VERSION ""

NS_ :

BS_:

BU_: XXX

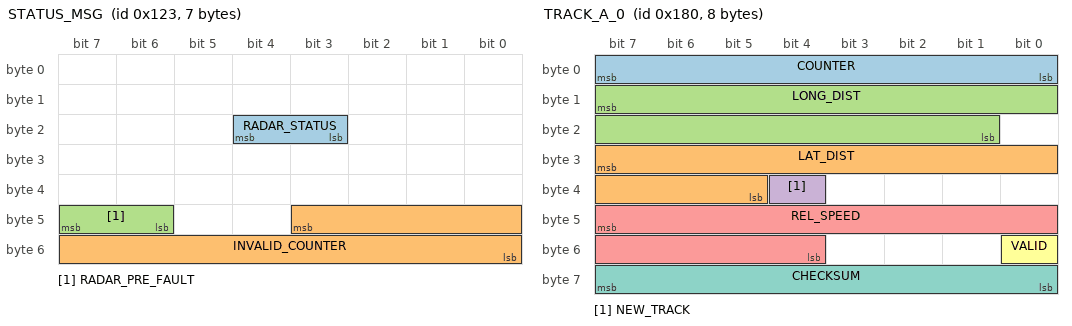
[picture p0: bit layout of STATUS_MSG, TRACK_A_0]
BO_ 291 STATUS_MSG: 7 XXX
 SG_ RADAR_STATUS : 20|2@0+ (1,0) [0|3] "" XXX
 SG_ INVALID_COUNTER : 43|12@0+ (1,0) [0|4095] "" XXX
 SG_ RADAR_PRE_FAULT : 47|2@0+ (1,0) [0|3] "" XXX

BO_ 384 TRACK_A_0: 8 XXX
 SG_ COUNTER : 7|8@0+ (1,0) [0|255] "" XXX
 SG_ LAT_DIST : 31|11@0- (0.04,0) [-50|50] "m" XXX
 SG_ LONG_DIST : 15|15@0+ (0.01,0) [0|300] "m" XXX
 SG_ NEW_TRACK : 36|1@0+ (1,0) [0|1] "" XXX
 SG_ REL_SPEED : 47|12@0- (0.025,0) [-100|100] "m/s" XXX
 SG_ VALID : 48|1@0+ (1,0) [0|1] "" XXX
 SG_ CHECKSUM : 63|8@0+ (1,0) [0|255] "" XXX

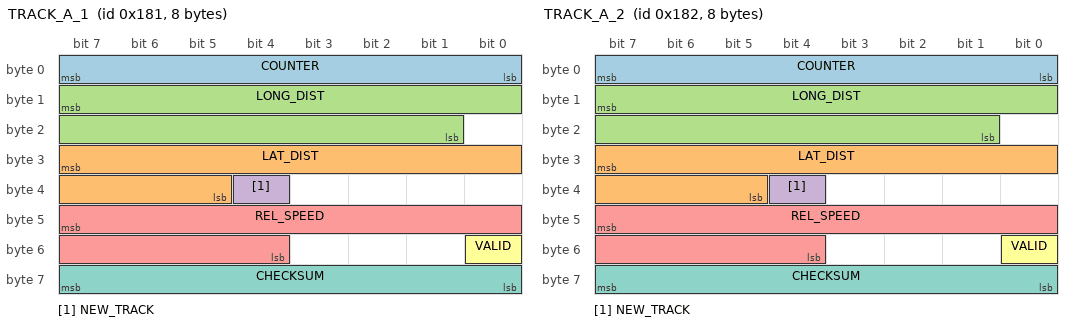
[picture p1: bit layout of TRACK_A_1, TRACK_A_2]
BO_ 385 TRACK_A_1: 8 XXX
 SG_ COUNTER : 7|8@0+ (1,0) [0|255] "" XXX
 SG_ LAT_DIST : 31|11@0- (0.04,0) [-50|50] "m" XXX
 SG_ LONG_DIST : 15|15@0+ (0.01,0) [0|300] "m" XXX
 SG_ NEW_TRACK : 36|1@0+ (1,0) [0|1] "" XXX
 SG_ REL_SPEED : 47|12@0- (0.025,0) [-100|100] "m/s" XXX
 SG_ VALID : 48|1@0+ (1,0) [0|1] "" XXX
 SG_ CHECKSUM : 63|8@0+ (1,0) [0|255] "" XXX

BO_ 386 TRACK_A_2: 8 XXX
 SG_ COUNTER : 7|8@0+ (1,0) [0|255] "" XXX
 SG_ LAT_DIST : 31|11@0- (0.04,0) [-50|50] "m" XXX
 SG_ LONG_DIST : 15|15@0+ (0.01,0) [0|300] "m" XXX
 SG_ NEW_TRACK : 36|1@0+ (1,0) [0|1] "" XXX
 SG_ REL_SPEED : 47|12@0- (0.025,0) [-100|100] "m/s" XXX
 SG_ VALID : 48|1@0+ (1,0) [0|1] "" XXX
 SG_ CHECKSUM : 63|8@0+ (1,0) [0|255] "" XXX

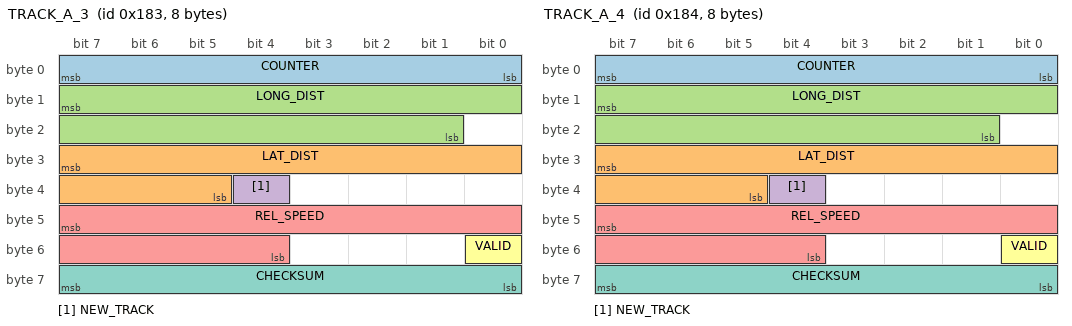
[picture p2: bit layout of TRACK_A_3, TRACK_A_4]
BO_ 387 TRACK_A_3: 8 XXX
 SG_ COUNTER : 7|8@0+ (1,0) [0|255] "" XXX
 SG_ LAT_DIST : 31|11@0- (0.04,0) [-50|50] "m" XXX
 SG_ LONG_DIST : 15|15@0+ (0.01,0) [0|300] "m" XXX
 SG_ NEW_TRACK : 36|1@0+ (1,0) [0|1] "" XXX
 SG_ REL_SPEED : 47|12@0- (0.025,0) [-100|100] "m/s" XXX
 SG_ VALID : 48|1@0+ (1,0) [0|1] "" XXX
 SG_ CHECKSUM : 63|8@0+ (1,0) [0|255] "" XXX

BO_ 388 TRACK_A_4: 8 XXX
 SG_ COUNTER : 7|8@0+ (1,0) [0|255] "" XXX
 SG_ LAT_DIST : 31|11@0- (0.04,0) [-50|50] "m" XXX
 SG_ LONG_DIST : 15|15@0+ (0.01,0) [0|300] "m" XXX
 SG_ NEW_TRACK : 36|1@0+ (1,0) [0|1] "" XXX
 SG_ REL_SPEED : 47|12@0- (0.025,0) [-100|100] "m/s" XXX
 SG_ VALID : 48|1@0+ (1,0) [0|1] "" XXX
 SG_ CHECKSUM : 63|8@0+ (1,0) [0|255] "" XXX

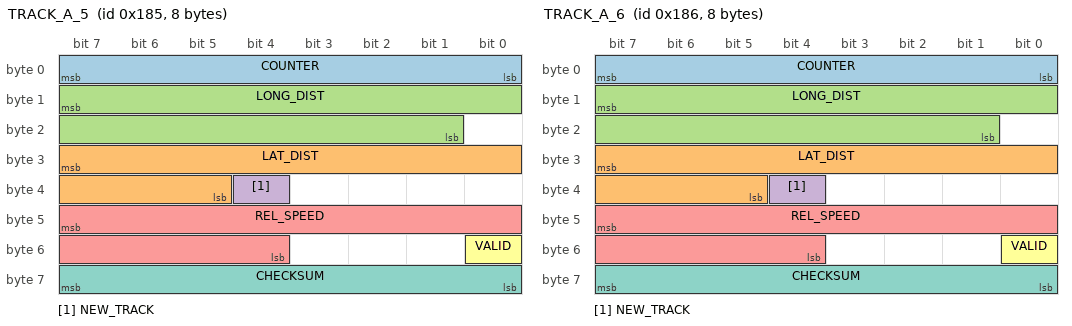
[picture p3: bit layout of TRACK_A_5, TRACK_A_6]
BO_ 389 TRACK_A_5: 8 XXX
 SG_ COUNTER : 7|8@0+ (1,0) [0|255] "" XXX
 SG_ LAT_DIST : 31|11@0- (0.04,0) [-50|50] "m" XXX
 SG_ LONG_DIST : 15|15@0+ (0.01,0) [0|300] "m" XXX
 SG_ NEW_TRACK : 36|1@0+ (1,0) [0|1] "" XXX
 SG_ REL_SPEED : 47|12@0- (0.025,0) [-100|100] "m/s" XXX
 SG_ VALID : 48|1@0+ (1,0) [0|1] "" XXX
 SG_ CHECKSUM : 63|8@0+ (1,0) [0|255] "" XXX

BO_ 390 TRACK_A_6: 8 XXX
 SG_ COUNTER : 7|8@0+ (1,0) [0|255] "" XXX
 SG_ LAT_DIST : 31|11@0- (0.04,0) [-50|50] "m" XXX
 SG_ LONG_DIST : 15|15@0+ (0.01,0) [0|300] "m" XXX
 SG_ NEW_TRACK : 36|1@0+ (1,0) [0|1] "" XXX
 SG_ REL_SPEED : 47|12@0- (0.025,0) [-100|100] "m/s" XXX
 SG_ VALID : 48|1@0+ (1,0) [0|1] "" XXX
 SG_ CHECKSUM : 63|8@0+ (1,0) [0|255] "" XXX

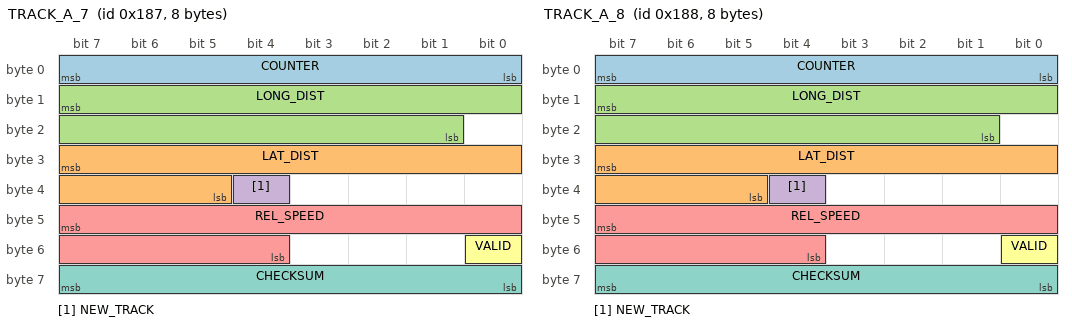
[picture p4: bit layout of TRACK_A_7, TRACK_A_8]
BO_ 391 TRACK_A_7: 8 XXX
 SG_ COUNTER : 7|8@0+ (1,0) [0|255] "" XXX
 SG_ LAT_DIST : 31|11@0- (0.04,0) [-50|50] "m" XXX
 SG_ LONG_DIST : 15|15@0+ (0.01,0) [0|300] "m" XXX
 SG_ NEW_TRACK : 36|1@0+ (1,0) [0|1] "" XXX
 SG_ REL_SPEED : 47|12@0- (0.025,0) [-100|100] "m/s" XXX
 SG_ VALID : 48|1@0+ (1,0) [0|1] "" XXX
 SG_ CHECKSUM : 63|8@0+ (1,0) [0|255] "" XXX

BO_ 392 TRACK_A_8: 8 XXX
 SG_ COUNTER : 7|8@0+ (1,0) [0|255] "" XXX
 SG_ LAT_DIST : 31|11@0- (0.04,0) [-50|50] "m" XXX
 SG_ LONG_DIST : 15|15@0+ (0.01,0) [0|300] "m" XXX
 SG_ NEW_TRACK : 36|1@0+ (1,0) [0|1] "" XXX
 SG_ REL_SPEED : 47|12@0- (0.025,0) [-100|100] "m/s" XXX
 SG_ VALID : 48|1@0+ (1,0) [0|1] "" XXX
 SG_ CHECKSUM : 63|8@0+ (1,0) [0|255] "" XXX

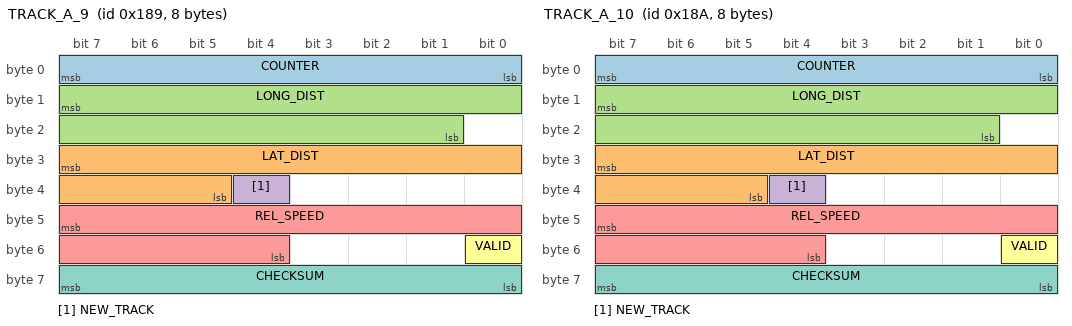
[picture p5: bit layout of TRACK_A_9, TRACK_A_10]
BO_ 393 TRACK_A_9: 8 XXX
 SG_ COUNTER : 7|8@0+ (1,0) [0|255] "" XXX
 SG_ LAT_DIST : 31|11@0- (0.04,0) [-50|50] "m" XXX
 SG_ LONG_DIST : 15|15@0+ (0.01,0) [0|300] "m" XXX
 SG_ NEW_TRACK : 36|1@0+ (1,0) [0|1] "" XXX
 SG_ REL_SPEED : 47|12@0- (0.025,0) [-100|100] "m/s" XXX
 SG_ VALID : 48|1@0+ (1,0) [0|1] "" XXX
 SG_ CHECKSUM : 63|8@0+ (1,0) [0|255] "" XXX

BO_ 394 TRACK_A_10: 8 XXX
 SG_ COUNTER : 7|8@0+ (1,0) [0|255] "" XXX
 SG_ LAT_DIST : 31|11@0- (0.04,0) [-50|50] "m" XXX
 SG_ LONG_DIST : 15|15@0+ (0.01,0) [0|300] "m" XXX
 SG_ NEW_TRACK : 36|1@0+ (1,0) [0|1] "" XXX
 SG_ REL_SPEED : 47|12@0- (0.025,0) [-100|100] "m/s" XXX
 SG_ VALID : 48|1@0+ (1,0) [0|1] "" XXX
 SG_ CHECKSUM : 63|8@0+ (1,0) [0|255] "" XXX

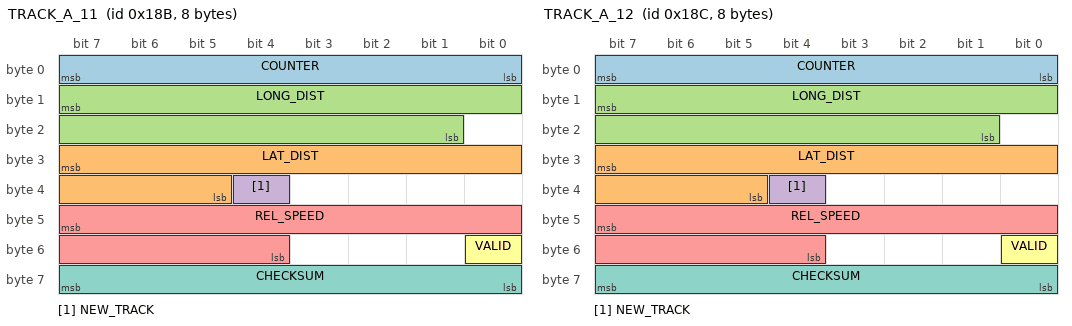
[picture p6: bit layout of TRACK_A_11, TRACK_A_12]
BO_ 395 TRACK_A_11: 8 XXX
 SG_ COUNTER : 7|8@0+ (1,0) [0|255] "" XXX
 SG_ LAT_DIST : 31|11@0- (0.04,0) [-50|50] "m" XXX
 SG_ LONG_DIST : 15|15@0+ (0.01,0) [0|300] "m" XXX
 SG_ NEW_TRACK : 36|1@0+ (1,0) [0|1] "" XXX
 SG_ REL_SPEED : 47|12@0- (0.025,0) [-100|100] "m/s" XXX
 SG_ VALID : 48|1@0+ (1,0) [0|1] "" XXX
 SG_ CHECKSUM : 63|8@0+ (1,0) [0|255] "" XXX

BO_ 396 TRACK_A_12: 8 XXX
 SG_ COUNTER : 7|8@0+ (1,0) [0|255] "" XXX
 SG_ LAT_DIST : 31|11@0- (0.04,0) [-50|50] "m" XXX
 SG_ LONG_DIST : 15|15@0+ (0.01,0) [0|300] "m" XXX
 SG_ NEW_TRACK : 36|1@0+ (1,0) [0|1] "" XXX
 SG_ REL_SPEED : 47|12@0- (0.025,0) [-100|100] "m/s" XXX
 SG_ VALID : 48|1@0+ (1,0) [0|1] "" XXX
 SG_ CHECKSUM : 63|8@0+ (1,0) [0|255] "" XXX

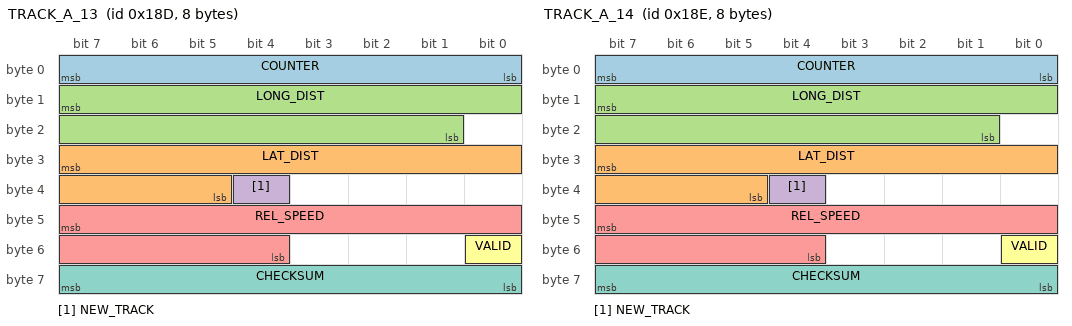
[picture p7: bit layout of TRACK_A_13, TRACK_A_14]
BO_ 397 TRACK_A_13: 8 XXX
 SG_ COUNTER : 7|8@0+ (1,0) [0|255] "" XXX
 SG_ LAT_DIST : 31|11@0- (0.04,0) [-50|50] "m" XXX
 SG_ LONG_DIST : 15|15@0+ (0.01,0) [0|300] "m" XXX
 SG_ NEW_TRACK : 36|1@0+ (1,0) [0|1] "" XXX
 SG_ REL_SPEED : 47|12@0- (0.025,0) [-100|100] "m/s" XXX
 SG_ VALID : 48|1@0+ (1,0) [0|1] "" XXX
 SG_ CHECKSUM : 63|8@0+ (1,0) [0|255] "" XXX

BO_ 398 TRACK_A_14: 8 XXX
 SG_ COUNTER : 7|8@0+ (1,0) [0|255] "" XXX
 SG_ LAT_DIST : 31|11@0- (0.04,0) [-50|50] "m" XXX
 SG_ LONG_DIST : 15|15@0+ (0.01,0) [0|300] "m" XXX
 SG_ NEW_TRACK : 36|1@0+ (1,0) [0|1] "" XXX
 SG_ REL_SPEED : 47|12@0- (0.025,0) [-100|100] "m/s" XXX
 SG_ VALID : 48|1@0+ (1,0) [0|1] "" XXX
 SG_ CHECKSUM : 63|8@0+ (1,0) [0|255] "" XXX

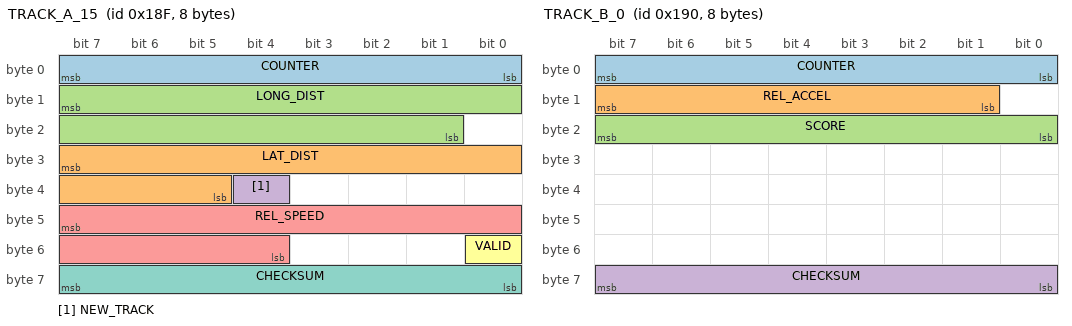
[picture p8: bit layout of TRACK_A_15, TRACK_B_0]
BO_ 399 TRACK_A_15: 8 XXX
 SG_ COUNTER : 7|8@0+ (1,0) [0|255] "" XXX
 SG_ LAT_DIST : 31|11@0- (0.04,0) [-50|50] "m" XXX
 SG_ LONG_DIST : 15|15@0+ (0.01,0) [0|300] "m" XXX
 SG_ NEW_TRACK : 36|1@0+ (1,0) [0|1] "" XXX
 SG_ REL_SPEED : 47|12@0- (0.025,0) [-100|100] "m/s" XXX
 SG_ VALID : 48|1@0+ (1,0) [0|1] "" XXX
 SG_ CHECKSUM : 63|8@0+ (1,0) [0|255] "" XXX

BO_ 400 TRACK_B_0: 8 XXX
 SG_ COUNTER : 7|8@0+ (1,0) [0|255] "" XXX
 SG_ REL_ACCEL : 15|7@0- (1,0) [-64|63] "" XXX
 SG_ SCORE : 23|8@0+ (1,0) [0|100] "" XXX
 SG_ CHECKSUM : 63|8@0+ (1,0) [0|255] "" XXX

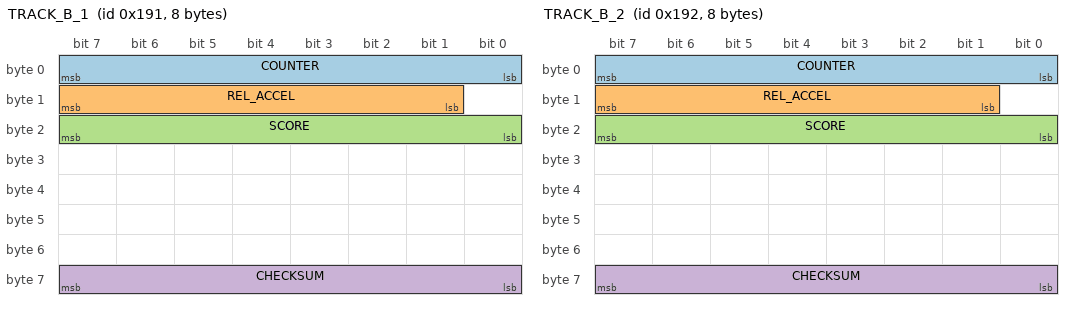
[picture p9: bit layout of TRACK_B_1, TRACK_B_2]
BO_ 401 TRACK_B_1: 8 XXX
 SG_ COUNTER : 7|8@0+ (1,0) [0|255] "" XXX
 SG_ REL_ACCEL : 15|7@0- (1,0) [-64|63] "" XXX
 SG_ SCORE : 23|8@0+ (1,0) [0|100] "" XXX
 SG_ CHECKSUM : 63|8@0+ (1,0) [0|255] "" XXX

BO_ 402 TRACK_B_2: 8 XXX
 SG_ COUNTER : 7|8@0+ (1,0) [0|255] "" XXX
 SG_ REL_ACCEL : 15|7@0- (1,0) [-64|63] "" XXX
 SG_ SCORE : 23|8@0+ (1,0) [0|100] "" XXX
 SG_ CHECKSUM : 63|8@0+ (1,0) [0|255] "" XXX

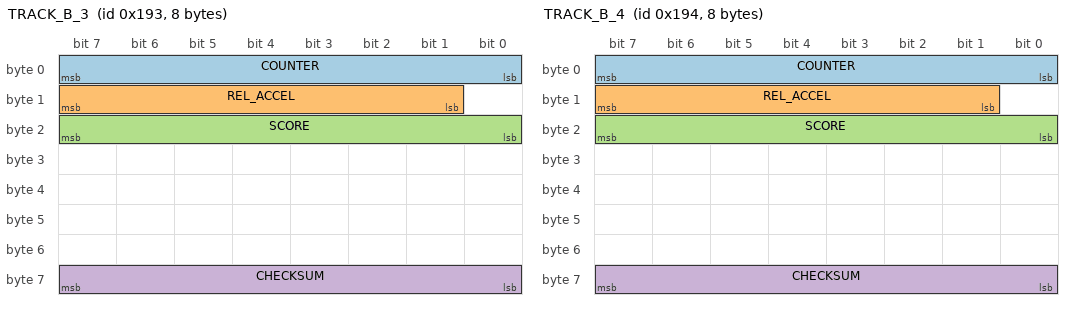
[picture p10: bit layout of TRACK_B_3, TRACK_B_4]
BO_ 403 TRACK_B_3: 8 XXX
 SG_ COUNTER : 7|8@0+ (1,0) [0|255] "" XXX
 SG_ REL_ACCEL : 15|7@0- (1,0) [-64|63] "" XXX
 SG_ SCORE : 23|8@0+ (1,0) [0|100] "" XXX
 SG_ CHECKSUM : 63|8@0+ (1,0) [0|255] "" XXX

BO_ 404 TRACK_B_4: 8 XXX
 SG_ COUNTER : 7|8@0+ (1,0) [0|255] "" XXX
 SG_ REL_ACCEL : 15|7@0- (1,0) [-64|63] "" XXX
 SG_ SCORE : 23|8@0+ (1,0) [0|100] "" XXX
 SG_ CHECKSUM : 63|8@0+ (1,0) [0|255] "" XXX

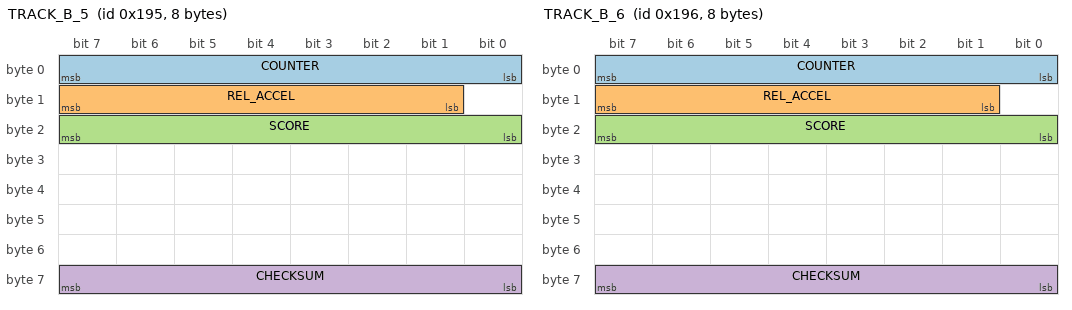
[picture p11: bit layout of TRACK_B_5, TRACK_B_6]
BO_ 405 TRACK_B_5: 8 XXX
 SG_ COUNTER : 7|8@0+ (1,0) [0|255] "" XXX
 SG_ REL_ACCEL : 15|7@0- (1,0) [-64|63] "" XXX
 SG_ SCORE : 23|8@0+ (1,0) [0|100] "" XXX
 SG_ CHECKSUM : 63|8@0+ (1,0) [0|255] "" XXX

BO_ 406 TRACK_B_6: 8 XXX
 SG_ COUNTER : 7|8@0+ (1,0) [0|255] "" XXX
 SG_ REL_ACCEL : 15|7@0- (1,0) [-64|63] "" XXX
 SG_ SCORE : 23|8@0+ (1,0) [0|100] "" XXX
 SG_ CHECKSUM : 63|8@0+ (1,0) [0|255] "" XXX

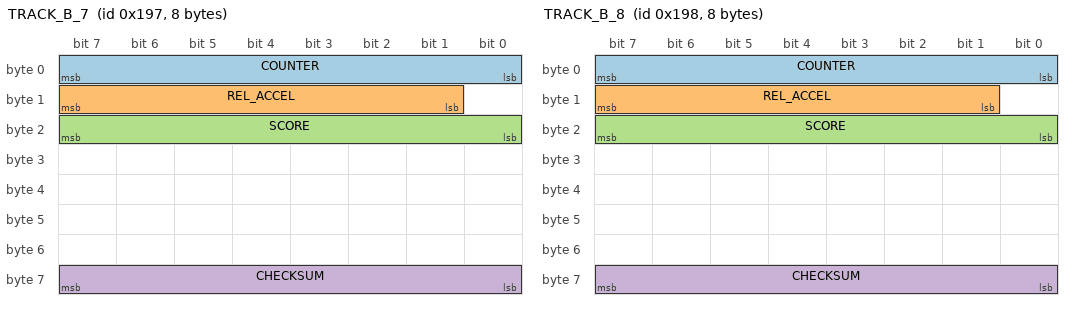
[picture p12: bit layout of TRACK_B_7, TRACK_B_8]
BO_ 407 TRACK_B_7: 8 XXX
 SG_ COUNTER : 7|8@0+ (1,0) [0|255] "" XXX
 SG_ REL_ACCEL : 15|7@0- (1,0) [-64|63] "" XXX
 SG_ SCORE : 23|8@0+ (1,0) [0|100] "" XXX
 SG_ CHECKSUM : 63|8@0+ (1,0) [0|255] "" XXX

BO_ 408 TRACK_B_8: 8 XXX
 SG_ COUNTER : 7|8@0+ (1,0) [0|255] "" XXX
 SG_ REL_ACCEL : 15|7@0- (1,0) [-64|63] "" XXX
 SG_ SCORE : 23|8@0+ (1,0) [0|100] "" XXX
 SG_ CHECKSUM : 63|8@0+ (1,0) [0|255] "" XXX

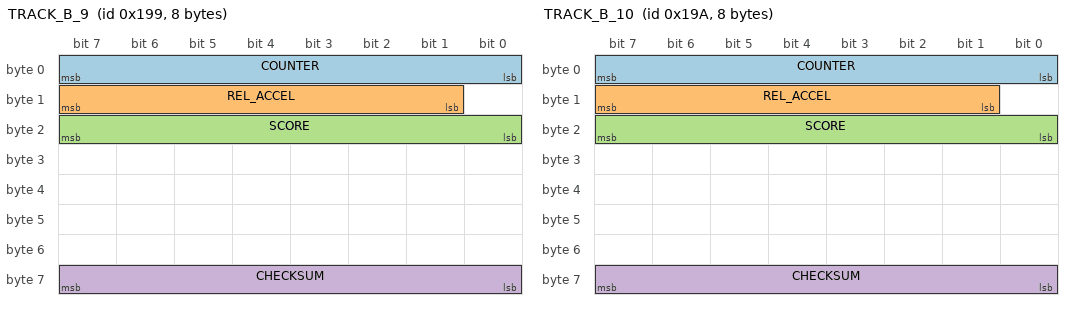
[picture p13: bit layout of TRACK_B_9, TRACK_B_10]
BO_ 409 TRACK_B_9: 8 XXX
 SG_ COUNTER : 7|8@0+ (1,0) [0|255] "" XXX
 SG_ REL_ACCEL : 15|7@0- (1,0) [-64|63] "" XXX
 SG_ SCORE : 23|8@0+ (1,0) [0|100] "" XXX
 SG_ CHECKSUM : 63|8@0+ (1,0) [0|255] "" XXX

BO_ 410 TRACK_B_10: 8 XXX
 SG_ COUNTER : 7|8@0+ (1,0) [0|255] "" XXX
 SG_ REL_ACCEL : 15|7@0- (1,0) [-64|63] "" XXX
 SG_ SCORE : 23|8@0+ (1,0) [0|100] "" XXX
 SG_ CHECKSUM : 63|8@0+ (1,0) [0|255] "" XXX

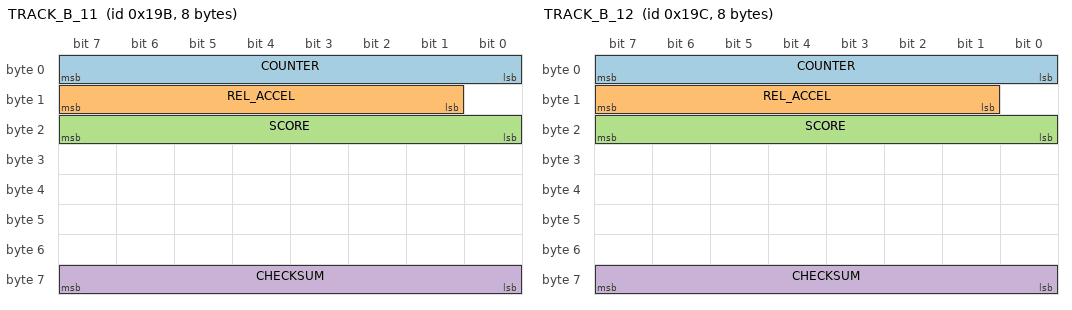
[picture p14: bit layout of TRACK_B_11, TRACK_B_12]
BO_ 411 TRACK_B_11: 8 XXX
 SG_ COUNTER : 7|8@0+ (1,0) [0|255] "" XXX
 SG_ REL_ACCEL : 15|7@0- (1,0) [-64|63] "" XXX
 SG_ SCORE : 23|8@0+ (1,0) [0|100] "" XXX
 SG_ CHECKSUM : 63|8@0+ (1,0) [0|255] "" XXX

BO_ 412 TRACK_B_12: 8 XXX
 SG_ COUNTER : 7|8@0+ (1,0) [0|255] "" XXX
 SG_ REL_ACCEL : 15|7@0- (1,0) [-64|63] "" XXX
 SG_ SCORE : 23|8@0+ (1,0) [0|100] "" XXX
 SG_ CHECKSUM : 63|8@0+ (1,0) [0|255] "" XXX

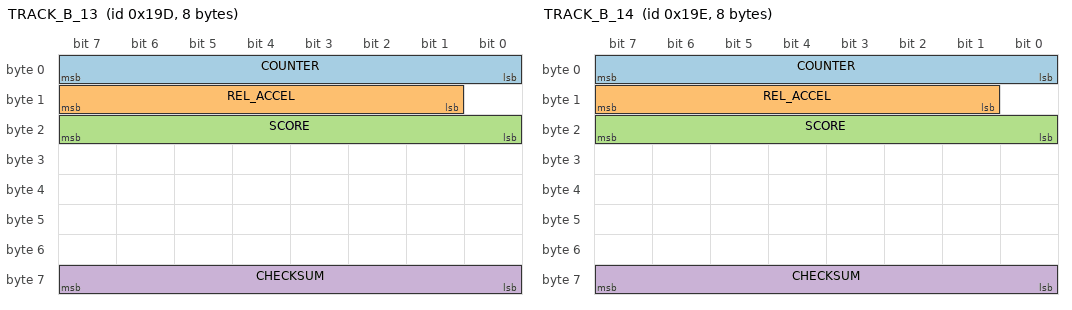
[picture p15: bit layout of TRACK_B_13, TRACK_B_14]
BO_ 413 TRACK_B_13: 8 XXX
 SG_ COUNTER : 7|8@0+ (1,0) [0|255] "" XXX
 SG_ REL_ACCEL : 15|7@0- (1,0) [-64|63] "" XXX
 SG_ SCORE : 23|8@0+ (1,0) [0|100] "" XXX
 SG_ CHECKSUM : 63|8@0+ (1,0) [0|255] "" XXX

BO_ 414 TRACK_B_14: 8 XXX
 SG_ COUNTER : 7|8@0+ (1,0) [0|255] "" XXX
 SG_ REL_ACCEL : 15|7@0- (1,0) [-64|63] "" XXX
 SG_ SCORE : 23|8@0+ (1,0) [0|100] "" XXX
 SG_ CHECKSUM : 63|8@0+ (1,0) [0|255] "" XXX

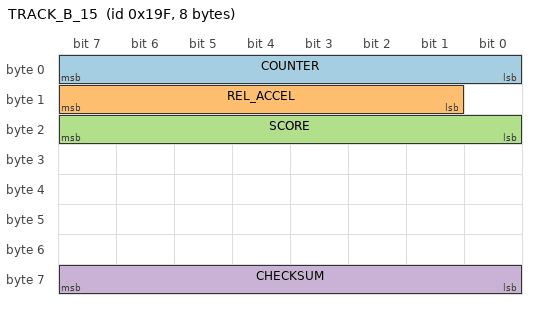
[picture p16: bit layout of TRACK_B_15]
BO_ 415 TRACK_B_15: 8 XXX
 SG_ COUNTER : 7|8@0+ (1,0) [0|255] "" XXX
 SG_ REL_ACCEL : 15|7@0- (1,0) [-64|63] "" XXX
 SG_ SCORE : 23|8@0+ (1,0) [0|100] "" XXX
 SG_ CHECKSUM : 63|8@0+ (1,0) [0|255] "" XXX

BO_ 576 NEW_MSG_1: 8 XXX
 SG_ NEW_SIGNAL_1 : 15|7@0+ (1,0) [0|127] "" XXX
 SG_ NEW_SIGNAL_2 : 23|8@0+ (1,0) [0|255] "" XXX

BO_ 577 NEW_MSG_2: 8 XXX
 SG_ NEW_SIGNAL_1 : 15|7@0+ (1,0) [0|127] "" XXX
 SG_ NEW_SIGNAL_2 : 23|8@0+ (1,0) [0|255] "" XXX

CM_ SG_ 291 RADAR_STATUS "Goes to 0 when radar is initializing, or car is at a standstill in non-US cars. Goes to 3 when INVALID_COUNTER is >= 2659 and throws dirty radar disable alert, or ACC is in non-adaptive mode.";
CM_ SG_ 291 INVALID_COUNTER "Unit unknown. Observed to rise when car is moving and radar is obstructed (object, snow, rain). Drops when obstruction is removed. Baseline is not the same across cars.";
CM_ SG_ 291 RADAR_PRE_FAULT "Goes to 3 when INVALID_COUNTER is >= 1358.";

VAL_ 291 RADAR_STATUS 0 "no points" 1 "ok" 3 "fault";
VAL_ 291 RADAR_PRE_FAULT 0 "ok" 3 "fault";
